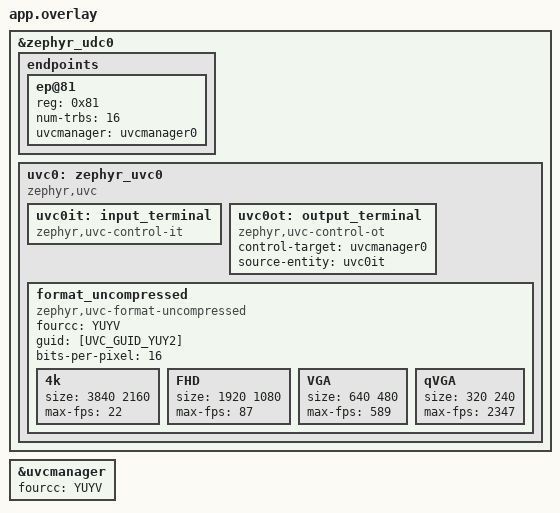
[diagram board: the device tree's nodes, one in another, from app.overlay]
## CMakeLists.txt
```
cmake_minimum_required(VERSION 3.20.0)
find_package(Zephyr REQUIRED HINTS $ENV{ZEPHYR_BASE})
project(app)
target_sources(app PRIVATE src/main.c src/usb.c)

# Run some code from RAM for performance during enumeration
zephyr_code_relocate(LIBRARY drivers__usb__udc LOCATION RAM)
```

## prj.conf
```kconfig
CONFIG_ASSERT=y

# Shell
CONFIG_SHELL=y
CONFIG_I2C_SHELL=y
CONFIG_KERNEL_SHELL=y
CONFIG_SHELL_BACKEND_SERIAL_CHECK_DTR=y

# Logging
CONFIG_LOG=y
CONFIG_LOG_MODE_MINIMAL=y
CONFIG_UDC_DRIVER_LOG_LEVEL_DBG=y
CONFIG_USBD_LOG_LEVEL_DBG=y
CONFIG_USBD_UVC_LOG_LEVEL_DBG=y
CONFIG_VIDEO_LOG_LEVEL_DBG=y

# USB
CONFIG_USBD_VIDEO_CLASS=y
CONFIG_USBD_VIDEO_HEADER_SIZE=8

# Video
CONFIG_VIDEO=y
CONFIG_VIDEO_UVCMANAGER=y
```

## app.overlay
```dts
/*
 * Copyright (c) 2024 tinyVision.ai Inc.
 * SPDX-License-Identifier: Apache-2.0
 */

#include <zephyr/dt-bindings/usb/video.h>

&zephyr_udc0 {
	endpoints {
		/* For USB UVC */
		ep@81 {
			reg = <0x81>;
			num-trbs = <16>;
			uvcmanager = <&uvcmanager0>;
		};
	};

	uvc0: zephyr_uvc0 {
		compatible = "zephyr,uvc";

		uvc0it: input_terminal {
			compatible = "zephyr,uvc-control-it";
		};
		uvc0ot: output_terminal {
			compatible = "zephyr,uvc-control-ot";
			control-target = <&uvcmanager0>;
			source-entity = <&uvc0it>;
		};

		format_uncompressed {
			compatible = "zephyr,uvc-format-uncompressed";
			fourcc = "YUYV";
			guid = [UVC_GUID_YUY2];
			bits-per-pixel = <16>;

			4k {
				size = <3840 2160>;
				max-fps = <22>;
			};

			FHD {
				size = <1920 1080>;
				max-fps = <87>;
			};

			VGA {
				size = <640 480>;
				max-fps = <589>;
			};

			qVGA {
				size = <320 240>;
				max-fps = <2347>;
			};
		};
	};
};

&uvcmanager {
	fourcc = "YUYV";
};
```

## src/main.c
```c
#include <zephyr/kernel.h>
#include <zephyr/devicetree.h>
#include <zephyr/drivers/video.h>
#include <zephyr/logging/log.h>

LOG_MODULE_REGISTER(app, LOG_LEVEL_DBG);

static const struct device *uvc0_dev = DEVICE_DT_GET(DT_NODELABEL(uvc0));

int main(void)
{
	struct video_buffer vbuf = {0};
	struct video_format fmt = {0};
	int err;

	/* Get the video format once it is selected by the host */
	while (true) {
		err = video_get_format(uvc0_dev, VIDEO_EP_IN, &fmt);
		if (err == 0) {
			break;
		}
		if (err != -EAGAIN) {
			LOG_ERR("failed to get the video format");
			return err;
		}

		k_sleep(K_MSEC(10));
	}

	/* The buffer address is the FIFO endpoint */
	vbuf.buffer = (void *)DT_REG_ADDR_BY_NAME(DT_NODELABEL(uvcmanager0), fifo);
	vbuf.size = vbuf.bytesused = fmt.pitch * fmt.height;
	vbuf.flags = VIDEO_BUF_EOF;

	LOG_DBG("frame %ux%u, %u bytes, addr %p", fmt.width, fmt.height, fmt.pitch * fmt.height, vbuf.buffer);

	/* Only the first buffer needs to be enqueued when using the UVC Manager */
	err = video_enqueue(uvc0_dev, VIDEO_EP_IN, &vbuf);
	if (err) {
		LOG_ERR("failed to enqueue the video buffer");
		return err;
	}

	k_sleep(K_FOREVER);
	return 0;
}
```

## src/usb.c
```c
#include <zephyr/drivers/usb/udc.h>
#include <zephyr/usb/usbd.h>
#include <zephyr/usb/bos.h>
#include <zephyr/logging/log.h>

LOG_MODULE_REGISTER(app_usb, LOG_LEVEL_DBG);

static const struct device *const udc0_dev = DEVICE_DT_GET(DT_NODELABEL(zephyr_udc0));

USBD_DEVICE_DEFINE(usbd, udc0_dev, 0x1209, 0x0001);

USBD_DESC_MANUFACTURER_DEFINE(usbd_manufacturer, "tinyVision.ai");
USBD_DESC_PRODUCT_DEFINE(usbd_product, "tinyCLUNX33");
USBD_DESC_LANG_DEFINE(usbd_lang);

static const struct usb_bos_capability_superspeed_usb bos_cap_ss = {
	.bLength = sizeof(struct usb_bos_capability_superspeed_usb),
	.bDescriptorType = USB_DESC_DEVICE_CAPABILITY,
	.bDevCapabilityType = USB_BOS_CAPABILITY_SUPERSPEED_USB,
	.bmAttributes = 0,
	.wSpeedsSupported = sys_cpu_to_le16(USB_BOS_SPEED_SUPERSPEED_GEN1 |
					    USB_BOS_SPEED_HIGHSPEED | USB_BOS_SPEED_FULLSPEED),
	.bFunctionnalSupport = 1,
	.bU1DevExitLat = 10,
	.wU2DevExitLat = sys_cpu_to_le16(1023),
};
USBD_DESC_BOS_DEFINE(usbd_bos_cap_ss, sizeof(bos_cap_ss), &bos_cap_ss);

static const struct usb_bos_capability_lpm bos_cap_lpm = {
	.bLength = sizeof(struct usb_bos_capability_lpm),
	.bDescriptorType = USB_DESC_DEVICE_CAPABILITY,
	.bDevCapabilityType = USB_BOS_CAPABILITY_EXTENSION,
	.bmAttributes = USB_BOS_ATTRIBUTES_LPM,
};
USBD_DESC_BOS_DEFINE(usbd_bos_cap_lpm, sizeof(bos_cap_lpm), &bos_cap_lpm);

USBD_CONFIGURATION_DEFINE(usbd_config, USB_SCD_SELF_POWERED, 100);

int app_usb_init(void)
{
	int err;

	LOG_DBG("Adding USB descriptors");
	err = usbd_add_descriptor(&usbd, &usbd_lang);
	if (err) {
		LOG_ERR("failed to add lang descriptor");
		return err;
	}
	err = usbd_add_descriptor(&usbd, &usbd_manufacturer);
	if (err) {
		LOG_ERR("failed to add manufacturer descriptor");
		return err;
	}
	err = usbd_add_descriptor(&usbd, &usbd_product);
	if (err) {
		LOG_ERR("failed to add product descriptor");
		return err;
	}
	err = usbd_add_descriptor(&usbd, &usbd_bos_cap_lpm);
	if (err) {
		LOG_ERR("failed to add bos_cap_lpm descriptor");
		return err;
	}
	err = usbd_add_descriptor(&usbd, &usbd_bos_cap_ss);
	if (err) {
		LOG_ERR("failed to add bos_cap_ss descriptor");
		return err;
	}

	LOG_DBG("Adding USB configuration");
	err = usbd_add_configuration(&usbd, USBD_SPEED_SS, &usbd_config);
	if (err) {
		LOG_ERR("failed to add SuperSpeed, configuration");
		return err;
	}

	usbd_device_set_code_triple(&usbd, USBD_SPEED_SS, USB_BCC_MISCELLANEOUS, 0x02, 0x01);

	LOG_DBG("Adding USB classes");
	err = usbd_register_all_classes(&usbd, USBD_SPEED_SS, 1);
	if (err) {
		LOG_ERR("failed to register USB clases");
		return err;
	}

	LOG_DBG("Finalize USB configuration");
	err = usbd_init(&usbd);
	if (err) {
		LOG_ERR("failed to initialize USB");
		return err;
	}

	LOG_DBG("Starting USB operation");
	err = usbd_enable(&usbd);
	if (err) {
		LOG_ERR("failed to enable the USB device");
		return err;
	}

	return 0;
}

SYS_INIT(app_usb_init, APPLICATION, CONFIG_APPLICATION_INIT_PRIORITY);
```
